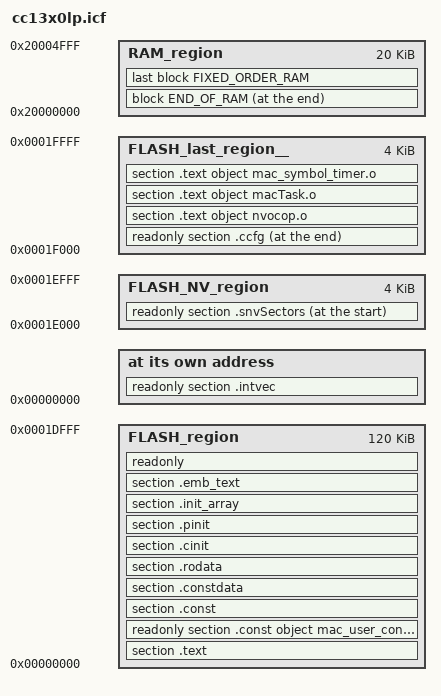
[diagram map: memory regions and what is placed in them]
/******************************************************************************

 @file  cc13x0lp.icf

 @brief IAR Linker configuration file for MAC-Sensor on CC13x0 LaunchPad

 Group: WCS LPC
 Target Device: cc13xx_cc26xx

 ******************************************************************************
 
 Copyright (c) 2016-2023, Texas Instruments Incorporated
 All rights reserved.

 Redistribution and use in source and binary forms, with or without
 modification, are permitted provided that the following conditions
 are met:

 *  Redistributions of source code must retain the above copyright
    notice, this list of conditions and the following disclaimer.

 *  Redistributions in binary form must reproduce the above copyright
    notice, this list of conditions and the following disclaimer in the
    documentation and/or other materials provided with the distribution.

 *  Neither the name of Texas Instruments Incorporated nor the names of
    its contributors may be used to endorse or promote products derived
    from this software without specific prior written permission.

 THIS SOFTWARE IS PROVIDED BY THE COPYRIGHT HOLDERS AND CONTRIBUTORS "AS IS"
 AND ANY EXPRESS OR IMPLIED WARRANTIES, INCLUDING, BUT NOT LIMITED TO,
 THE IMPLIED WARRANTIES OF MERCHANTABILITY AND FITNESS FOR A PARTICULAR
 PURPOSE ARE DISCLAIMED. IN NO EVENT SHALL THE COPYRIGHT OWNER OR
 CONTRIBUTORS BE LIABLE FOR ANY DIRECT, INDIRECT, INCIDENTAL, SPECIAL,
 EXEMPLARY, OR CONSEQUENTIAL DAMAGES (INCLUDING, BUT NOT LIMITED TO,
 PROCUREMENT OF SUBSTITUTE GOODS OR SERVICES; LOSS OF USE, DATA, OR PROFITS;
 OR BUSINESS INTERRUPTION) HOWEVER CAUSED AND ON ANY THEORY OF LIABILITY,
 WHETHER IN CONTRACT, STRICT LIABILITY, OR TORT (INCLUDING NEGLIGENCE OR
 OTHERWISE) ARISING IN ANY WAY OUT OF THE USE OF THIS SOFTWARE,
 EVEN IF ADVISED OF THE POSSIBILITY OF SUCH DAMAGE.

 ******************************************************************************
 
 
 *****************************************************************************/

/* Intvec start */
define symbol FLASH_BASE__ = 0x00000000;
define symbol WORD_SIZE           = 4;
define symbol FLASH_MEM_ALIGN     = WORD_SIZE;


/* Memory Regions */
if (isdefinedsymbol(ONE_PAGE_NV)) {
	define symbol FLASH_NV_base__  = 0x0001E000; // NV Flash base
	define symbol FLASH_NV_size__  = 0x00001000;
    define symbol FLASH_SIZE__     = 0x0001E000;
}
else {
	define symbol FLASH_NV_base__  = 0x0001D000; // NV Flash base
	define symbol FLASH_NV_size__  = 0x00002000;
    define symbol FLASH_SIZE__     = 0x0001D000;
}

define symbol FLASH_LAST_base__     = 0x0001F000;
define symbol FLASH_LAST_size__    = 0x00001000;

define symbol RAM_base__           = 0x20000000;
define symbol RAM_size__           = 0x5000;

/* Define a memory region that covers the entire 4 GB addressable space */
define memory mem with size = 4G;

/* Define a region for the on-chip flash */
define region FLASH_region = mem:[from FLASH_BASE__ size FLASH_SIZE__];

/* Define a region for the on-chip flash used for NV storage */
define region FLASH_NV_region = mem:[from FLASH_NV_base__ size FLASH_NV_size__];

/* Define a region for the last flash page */
define region FLASH_last_region__ = mem:[from FLASH_LAST_base__ size FLASH_LAST_size__];

/* Internal RAM for data used by application */
define region RAM_region = mem:[from RAM_base__ size RAM_size__];

/* Place the interrupt vectors at the start of flash */
place at address mem:FLASH_BASE__ { readonly section .intvec };
keep { section .intvec};

/* Place the CCA area at the end of flash */
place at end of FLASH_last_region__ { readonly section .ccfg };
keep { section .ccfg };

place in FLASH_last_region__ { section .text object nvocop.o  };
place in FLASH_last_region__ { section .text object macTask.o };
place in FLASH_last_region__ { section .text object mac_symbol_timer.o };

place in FLASH_region { section .text };

place in FLASH_region { readonly section .const object mac_user_config.o };

place in FLASH_region { 
	section .const,
	section .constdata,
	section .rodata,
	section .cinit,
	section .pinit,
	section .init_array,
	section .emb_text
};

/* Place remaining 'read only' in Flash */
place in FLASH_region { readonly };

/* Mark the beginning of the NV Flash page */
place at start of FLASH_NV_region { readonly section .snvSectors };


/* Place in RAM */

define block IMAGE {
    section .vtable_ram, 
	section .data,
	section .bss,
	section .vtable,
	section .sysmem,
	section .nonretenvar,
};

/*
 * Define CSTACK block to contain .stack section. This enables the IAR IDE
 * to properly show the stack content during debug. Place stack at end of
 * retention RAM, do not initialize (initializing the stack will destroy the
 * return address from the initialization code, causing the processor to branch
 * to zero and fault)
 */
define symbol STACKSIZE = 1024;
define block CSTACK with alignment = 8, size = STACKSIZE { section .stack };

define section .heap_start            { public heapStart: };
define section .heap_end              { public heapEnd: };
define block   HEAP_END with size = 1 { section .heap_end };

define block END_OF_RAM with fixed order {
                                        block HEAP_END,
                                        block CSTACK
                                      };
place at end of RAM_region { block END_OF_RAM };

define block RWDATA { readwrite };

define block FIXED_ORDER_RAM with fixed order { block IMAGE, block RWDATA};
place in RAM_region {last block FIXED_ORDER_RAM};


//place at end of RAM_region { block CSTACK };

/* Export stack top symbol. Used by startup file */
define exported symbol STACK_TOP = end(RAM_region) + 1;

initialize by copy { readwrite };
do not initialize { section .stack, section .noinit};

/*
 * The USE_TIRTOS_ROM symbol is defined internally in the build flow (using
 * --config_def USE_TIRTOS_ROM=1) for TI-RTOS applications whose app.cfg file
 * specifies to use the ROM.
 */
if (isdefinedsymbol(USE_TIRTOS_ROM)) {
    include "TIRTOS_ROM.icf";
}
